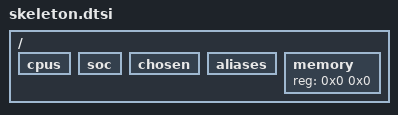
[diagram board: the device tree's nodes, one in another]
/*
 * Skeleton device tree; the bare minimum needed to boot; just include and
 * add a compatible value.  The bootloader will typically populate the memory
 * node.
 */

/ {
	#address-cells = <0x1>;
	#size-cells = <0x1>;
	cpus { };
	soc { };
	chosen { };
	aliases { };
	memory { device_type = "memory"; reg = <0x0 0x0>; };
};
